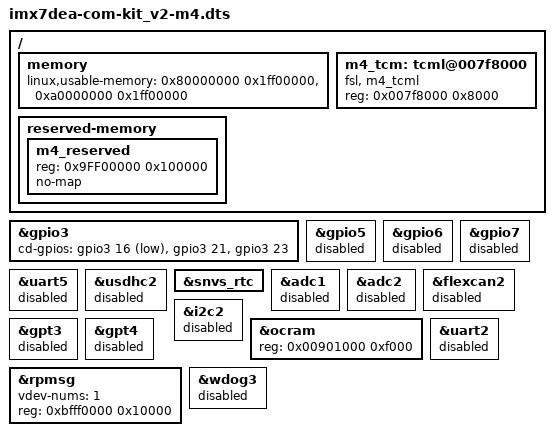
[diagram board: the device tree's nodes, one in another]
/*
 * Copyright (C) 2015 Freescale Semiconductor, Inc.
 *
 * This program is free software; you can redistribute it and/or modify
 * it under the terms of the GNU General Public License version 2 as
 * published by the Free Software Foundation.
 */

#include "imx7dea-com-kit_v2.dts"


/{
	memory {
		linux,usable-memory = <0x80000000 0x1ff00000>,
				<0xa0000000 0x1ff00000>;
	};
	reserved-memory {
                m4_reserved{
                        reg = <0x9FF00000 0x100000>;
                        no-map;
                };
		/*linux,cma {
			size = <0x2000000>;
		};*/
};/*vf*/

	m4_tcm: tcml@007f8000 {
		compatible = "fsl, m4_tcml";
		reg = <0x007f8000 0x8000>;
	};
};
&gpio3 {
	cd-gpios = <&gpio3 16 GPIO_ACTIVE_LOW>, <&gpio3 21 GPIO_ACTIVE_HIGH, <&gpio3 23 GPIO_ACTIVE_HIGH>;
	status = "okay";
};
&gpio5 {
	status = "disabled";
};

&gpio6 {
	status = "disabled";
};

&gpio7 {
	status = "disabled";
};

&uart5 {
	status = "disabled";
};//vf

&usdhc2 {
        status = "disabled";
};//vf

&snvs_rtc {
   status = "okay";
};//vf

&adc1 {
	status = "disabled";
};

&adc2 {
	status = "disabled";
};

&flexcan2 {
	status = "disabled";
};

&i2c2 {
	status = "disabled";
};

&gpt3 {
	status = "disabled";
};

&gpt4 {
	status = "disabled";
};

&ocram {
	reg = <0x00901000 0xf000>;
};

&rpmsg{
	vdev-nums = <1>;
	reg = <0xbfff0000 0x10000>;
	status = "okay";
};

&uart2 {
	status = "disabled";
};

&wdog3{
	status = "disabled";
};
